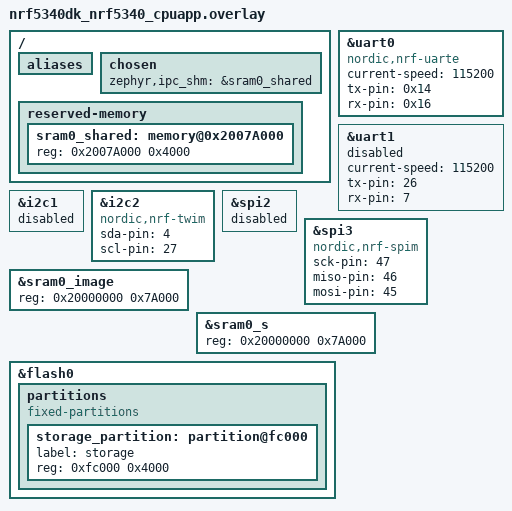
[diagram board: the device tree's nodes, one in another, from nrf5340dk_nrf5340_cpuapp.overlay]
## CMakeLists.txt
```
# SPDX-License-Identifier: Apache-2.0

cmake_minimum_required(VERSION 3.13.1)

find_package(Zephyr REQUIRED HINTS $ENV{ZEPHYR_BASE})
project(comprensive_example)

# NORDIC SDK APP START

target_sources(app PRIVATE src/main.c)

target_sources_ifdef(CONFIG_EXAMPLE_IIC app
                     PRIVATE src/iic_thread.c)
					 
target_sources_ifdef(CONFIG_EXAMPLE_SPIM app
                     PRIVATE src/spi_thread.c)
					 
target_sources_ifdef(CONFIG_EXAMPLE_HS_UART app
                     PRIVATE src/uart_thread.c)
					 
target_sources_ifdef(CONFIG_EXAMPLE_ADC app
                     PRIVATE src/adc_thread.c)
					 
target_sources_ifdef(CONFIG_RPC_REMOTE_API app
                     PRIVATE src/rpc_app_api_general.c src/rpc_app_api.c src/rpc_thread.c)
				 

target_sources_ifdef(CONFIG_RPC_SMP_BT app
                     PRIVATE src/rpc_app_smp_bt.c)		

target_sources_ifdef(CONFIG_EXAMPLE_FLASH app
                     PRIVATE src/flash_thread.c)

target_sources_ifdef(CONFIG_EXAMPLE_RAW_NRFX app
                      PRIVATE src/raw_nrfx_driver_thread.c)


zephyr_library_include_directories(.)

# NORDIC SDK APP END
```

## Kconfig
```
#
# Copyright (c) 2018 Nordic Semiconductor ASA
#
# SPDX-License-Identifier: LicenseRef-BSD-5-Clause-Nordic
#

source "Kconfig.zephyr"
menu "nRF53 BLE custom"

config BLE_NETWORK_CORE
	bool "Both BLE host and controller run on network core"
	help
	  Enable the whole BLE stack running on network core

config EXAMPLE_IIC
	bool "load IIC example or not"
	help
		if yes, load IIC example
		
config EXAMPLE_SPIM
	bool "load SPI master example or not"
	help
		if yes, load SPI master example		
		
config EXAMPLE_EXT_INT
	bool "load external IO interrupt example or not"
	help
		if yes, load external IO interrupt example

config EXAMPLE_ADC
	bool "load ADC example or not"
	help
		if yes, load ADC example		

config EXAMPLE_HS_UART
	bool "load high speed UART example or not"
	help
		if yes, load high speed UART example	  

config EXAMPLE_FLASH
	bool "load Flash access usage example"
	default n
	help
		if yes, load Flash access usage example

config EXAMPLE_RAW_NRFX
	bool "load raw nrfx driver(spim3 & rtc) usage example"
	default n
	help
		if yes, load raw spim3 & rtc API usage example	

config RPC_REMOTE_API
	bool "app core and net core communicate by remote API. that is, app core can call net core API, and net core can also call app core API"
	help
	  enable the RPC api mode
	  
config RPC_SMP_BT
	bool "(test purpose) load DFU example over BLE SMP"
	help
		if yes, load DFU example over BLE SMP		

config NCS_OLD
	bool "use NCS v1.5.1 or earlier API"
	help
		use NCS v1.5.1 or earlier API
		
module = NRF53_EXAMPLES_CONFIG
module-str = nrf53 specific examples configurations
source "${ZEPHYR_BASE}/subsys/logging/Kconfig.template.log_config"

endmenu
```

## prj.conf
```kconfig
CONFIG_NFCT_PINS_AS_GPIOS=y

## thread monitor ##
CONFIG_THREAD_ANALYZER=y
CONFIG_THREAD_NAME=y

## logging configurations ##
CONFIG_ASSERT=y
CONFIG_ASSERT_LEVEL=2

CONFIG_LOG=y
CONFIG_LOG_DEFAULT_LEVEL=3
CONFIG_LOG_BACKEND_UART=y
CONFIG_LOG_BACKEND_RTT=n
CONFIG_LOG_BACKEND_RTT_MODE_DROP=y
CONFIG_LOG_MODE_OVERFLOW=y
CONFIG_LOG_PRINTK=y
CONFIG_LOG_PRINTK_MAX_STRING_LENGTH=256
CONFIG_LOG_BUFFER_SIZE=4096
CONFIG_LOG_BACKEND_RTT_MESSAGE_SIZE=256
CONFIG_LOG_STRDUP_BUF_COUNT=64
CONFIG_LOG_STRDUP_MAX_STRING=64
CONFIG_LOG_BACKEND_SHOW_COLOR=n
CONFIG_LOG_BACKEND_FORMAT_TIMESTAMP=y
## CONFIG_LOG_IMMEDIATE=y

CONFIG_CONSOLE=y
CONFIG_USE_SEGGER_RTT=n
CONFIG_SEGGER_RTT_BUFFER_SIZE_UP=4096
CONFIG_RTT_CONSOLE=n
CONFIG_UART_CONSOLE=y

#change logging backend to RTT
# CONFIG_LOG_BACKEND_UART=n
# CONFIG_LOG_BACKEND_RTT=y
# CONFIG_USE_SEGGER_RTT=y
# CONFIG_RTT_CONSOLE=y
# CONFIG_UART_CONSOLE=n

## peripherals ##
CONFIG_GPIO=y
CONFIG_DK_LIBRARY=y

## stack size configurations ##
CONFIG_SYSTEM_WORKQUEUE_STACK_SIZE=2400
# CONFIG_ISR_STACK_SIZE=2048
CONFIG_HEAP_MEM_POOL_SIZE=12288
CONFIG_LOG_PROCESS_THREAD_STACK_SIZE=1024
CONFIG_MAIN_STACK_SIZE=2048

# enable network core
CONFIG_BOARD_ENABLE_CPUNET=y


## RPC example configurations ##
CONFIG_RPC_REMOTE_API=y

CONFIG_IPM=y
CONFIG_IPM_NRFX=y
CONFIG_IPM_MSG_CH_1_ENABLE=y
CONFIG_IPM_MSG_CH_1_TX=y
CONFIG_IPM_MSG_CH_0_ENABLE=y
CONFIG_IPM_MSG_CH_0_RX=y
CONFIG_OPENAMP=y
CONFIG_NRF_RPC=y

CONFIG_TINYCBOR=y
CONFIG_RPMSG_MASTER=y
CONFIG_THREAD_CUSTOM_DATA=y
CONFIG_NRF_RPC_CBOR=y
CONFIG_NRF_RPC_THREAD_STACK_SIZE=2048
CONFIG_NRF_RPC_LOG_LEVEL_INF=y
CONFIG_NRF_RPC_TR_LOG_LEVEL_INF=y
CONFIG_NRF_RPC_OS_LOG_LEVEL_INF=y


## I2C master example ##
CONFIG_EXAMPLE_IIC=y
CONFIG_I2C=y
CONFIG_NRFX_TWIM=y
CONFIG_NRFX_TWIM2=y

## external interrupt example (in IIC thread) ##
CONFIG_EXAMPLE_EXT_INT=y

## high speed uart example ##
CONFIG_EXAMPLE_HS_UART=y
CONFIG_SERIAL=y
CONFIG_UART_ASYNC_API=y
CONFIG_NRFX_UARTE1=y
CONFIG_UART_1_NRF_HW_ASYNC=y
CONFIG_UART_1_NRF_HW_ASYNC_TIMER=2
CONFIG_NRFX_UARTE0=y
CONFIG_UART_0_NRF_HW_ASYNC=y
CONFIG_UART_0_NRF_HW_ASYNC_TIMER=1

## SPI master example ##
CONFIG_EXAMPLE_SPIM=y
CONFIG_SPI=y
CONFIG_NRFX_SPIM3=y

## raw nrfx(spim3 & rtc0) driver API usage example ##
# CONFIG_EXAMPLE_RAW_NRFX=y
# CONFIG_NRFX_SPIM3=y
# CONFIG_NRFX_RTC0=y

## Load ADC example ##
CONFIG_EXAMPLE_ADC=y
CONFIG_ADC=y
CONFIG_ADC_ASYNC=y
CONFIG_ADC_NRFX_SAADC=y

## Flash access usage example ##
CONFIG_EXAMPLE_FLASH=y
CONFIG_FLASH=y
CONFIG_FLASH_PAGE_LAYOUT=y
CONFIG_FLASH_MAP=y
CONFIG_NVS=y
CONFIG_MPU_ALLOW_FLASH_WRITE=y
CONFIG_SETTINGS=y

## Device power management example ##
## CONFIG_DEVICE_POWER_MANAGEMENT is deprecated from NCSv1.5.0. Use CONFIG_PM_DEVICE instead
CONFIG_PM_DEVICE=y

## common DFU setting ##
CONFIG_BLE_NETWORK_CORE=y
CONFIG_NRF53_UPGRADE_NETWORK_CORE=y
CONFIG_BOOTLOADER_MCUBOOT=y

## Open the following config to run SMP DFU ##
# CONFIG_MCUMGR=y
# CONFIG_MCUMGR_CMD_IMG_MGMT=y
# CONFIG_MCUMGR_CMD_OS_MGMT=y
# CONFIG_OS_MGMT_TASKSTAT=n
# CONFIG_OS_MGMT_ECHO=y
# CONFIG_IMG_BLOCK_BUF_SIZE=2048
# CONFIG_MCUMGR_BUF_SIZE=256
# CONFIG_MCUMGR_BUF_COUNT=4
# CONFIG_MGMT_CBORATTR_MAX_SIZE=512
# ## CONFIG_IMG_ERASE_PROGRESSIVELY=y

# ## SMP BLE DFU via RPC config ##
# CONFIG_RPC_SMP_BT=y

## SMP UART DFU config ##
# CONFIG_MCUMGR_SMP_UART=y
# CONFIG_UART_MCUMGR_RX_BUF_SIZE=256
# CONFIG_UART_MCUMGR_RX_BUF_COUNT=2
# CONFIG_UART_0_INTERRUPT_DRIVEN=y

## Open the following config to run nrf_dfu OTA ##
CONFIG_NRF_DFU=y
CONFIG_NRF_DFU_RPC_APP=y
# CONFIG_NRF_DFU_LOG_LEVEL=3
CONFIG_IMG_MANAGER=y
CONFIG_MCUBOOT_IMG_MANAGER=y
CONFIG_IMG_BLOCK_BUF_SIZE=4096

## Open the following kconfig to put secondary slot on external Flash ##
## mcuboot.conf should do the correspondent changes too ##
CONFIG_PM_EXTERNAL_FLASH=y
CONFIG_PM_EXTERNAL_FLASH_DEV_NAME="MX25R64"
CONFIG_PM_EXTERNAL_FLASH_BASE=0x0
CONFIG_PM_EXTERNAL_FLASH_SIZE=0x800000
CONFIG_NORDIC_QSPI_NOR=y
CONFIG_NORDIC_QSPI_NOR_FLASH_LAYOUT_PAGE_SIZE=4096
CONFIG_NORDIC_QSPI_NOR_STACK_WRITE_BUFFER_SIZE=16
# Set the settings storage size
CONFIG_PM_PARTITION_SIZE_SETTINGS_STORAGE=0x4000

## To run the example in NCS v1.5.1 or earlier, open the following configurations
# CONFIG_NCS_V1_5_1=y
```

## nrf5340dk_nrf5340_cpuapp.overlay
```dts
/* overlay file for app core */

&uart0 {
	compatible = "nordic,nrf-uarte";
	status = "okay";
	current-speed = < 115200 >;	
	tx-pin = < 0x14 >;
	rx-pin = < 0x16 >;
	/* delete rts-pin&cts-pin to release the related 2 pins for other uses */
	/delete-property/ rts-pin;
	/delete-property/ cts-pin;
};

&uart1 {
	status = "disabled";
	current-speed = < 115200 >;
	tx-pin = < 26 >;
	rx-pin = < 7 >;
};

&i2c1 {
	status = "disabled";
};

&i2c2 {
	status = "okay";
	compatible = "nordic,nrf-twim";
	sda-pin = <4>;
	scl-pin = <27>;
};

&spi2 {
	status = "disabled";
};

&spi3 {
	status = "okay"; 
	compatible = "nordic,nrf-spim";
	sck-pin = < 47 >;
	miso-pin = < 46 >;
	mosi-pin = < 45 >;
};

/* delete button4 to initialize the related pin for network core use */
/ {
 aliases {  
  /delete-property/ sw3;
 };
};

/delete-node/ &button3;

/* adjust the RAM size of application image */
&sram0_image{
	reg = < 0x20000000 0x7A000 >;
};

&sram0_s{
	reg = < 0x20000000 0x7A000 >;
};

/delete-node/ &sram0_shared;

/ {
	chosen {
		/* shared memory reserved for the inter-processor communication */
		zephyr,ipc_shm = &sram0_shared;
	};

	reserved-memory {
		#address-cells = <1>;
		#size-cells = <1>;
		ranges;	
		sram0_shared: memory@0x2007A000 {
			/* SRAM allocated to shared memory */
			reg = <0x2007A000 0x4000>;
		};
	};
};

/delete-node/ &storage_partition;
&flash0{
		partitions {
			compatible = "fixed-partitions";
			#address-cells = < 0x1 >;
			#size-cells = < 0x1 >;

			storage_partition: partition@fc000 {
				label = "storage";
				reg = < 0xfc000 0x4000 >;
			};
		};
};
```

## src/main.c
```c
/*
 * Copyright (c) 2020 Nordic Semiconductor ASA
 *
 * SPDX-License-Identifier: LicenseRef-BSD-5-Clause-Nordic
 */

#include <zephyr.h>
#include <device.h>
#include <devicetree.h>
#include <drivers/gpio.h>
#include <stdio.h>
#include <dk_buttons_and_leds.h>
#include <nrf.h>
#include <nrfx.h>
#include <drivers/uart.h>
#ifdef CONFIG_MCUMGR_CMD_IMG_MGMT
#include "img_mgmt/img_mgmt.h"
#endif
#ifdef CONFIG_MCUMGR_CMD_OS_MGMT
#include "os_mgmt/os_mgmt.h"
#endif
#ifdef CONFIG_RPC_SMP_BT
#include "rpc_app_smp_bt.h"
#include <img_mgmt/img_mgmt_impl.h>
#endif
#ifdef CONFIG_NRF_DFU
#include "nrf_dfu_settings.h"
#include "nrf_dfu.h"
#include "power/reboot.h"
#include "nrf_dfu.h"
#include "nrf_dfu_validation.h"
#endif
#include <logging/log.h>
#include <logging/log_ctrl.h>
#define LOG_MODULE_NAME main
LOG_MODULE_REGISTER(LOG_MODULE_NAME);

#define ERASE_DELAY_AFTER_BOOT 30   //unit: s
#ifndef CONFIG_NCS_V1_5_1
static struct k_work_delayable blinky_work;
#else
static struct k_delayed_work blinky_work;
#endif

K_SEM_DEFINE(sem_rpc_tx, 0, 1);
K_SEM_DEFINE(sem_spi_txrx, 0, 1);
K_SEM_DEFINE(sem_raw_nrfx_txrx, 0, 1);
/* Stack definition for application workqueue */
K_THREAD_STACK_DEFINE(application_stack_area,
		      1024);
static struct k_work_q application_work_q;

/* The devicetree node identifier for the "led0" alias. */
#define LED0_NODE DT_ALIAS(led0)

#if DT_NODE_HAS_STATUS(LED0_NODE, okay)
#define LED0	DT_GPIO_LABEL(LED0_NODE, gpios)
#define LED0_PIN	DT_GPIO_PIN(LED0_NODE, gpios)
#define LED0_FLAGS	DT_GPIO_FLAGS(LED0_NODE, gpios)
#else
/* A build error here means your board isn't set up to blink an LED. */
#error "Unsupported board: led0 devicetree alias is not defined"
#define LED0	""
#define PIN	0
#define FLAGS	0
#endif

#ifdef CONFIG_PM_DEVICE

const struct device *devUart0;
const struct device *devUart1;

static void get_device_handle(void)
{
	devUart0 = device_get_binding("UART_0");
    devUart1 = device_get_binding("UART_1");
}
#ifdef CONFIG_NCS_V1_5_1
void set_device_pm_state(void)
{
	int err;
	uint32_t pm_state;

	device_get_power_state(devUart1, &pm_state);
	if (pm_state == DEVICE_PM_SUSPEND_STATE)
	{
		LOG_INF("UART1 is in suspend state. We activate it");
		err = device_set_power_state(devUart1,
						DEVICE_PM_ACTIVE_STATE,
						NULL, NULL);
		if (err) {
			LOG_ERR("UART1 enable failed");			
		}
		else
		{
			LOG_INF("## UART1 is actvie now ##");
		}		
	}
	else if (pm_state == DEVICE_PM_ACTIVE_STATE)
	{
		LOG_INF("UART1 is in active state. We suspend it");
		err = device_set_power_state(devUart1,
						DEVICE_PM_SUSPEND_STATE,
						NULL, NULL);
		if (err) {
			LOG_ERR("UART1 disable failed");
		}
		else
		{
			LOG_INF("## UART1 is suspended now ##");
		}		
	}



	device_get_power_state(devUart0, &pm_state);
	if (pm_state == DEVICE_PM_SUSPEND_STATE)
	{
		LOG_INF("UART0 is in suspend state. We activate it");
		err = device_set_power_state(devUart0,
						DEVICE_PM_ACTIVE_STATE,
						NULL, NULL);
		if (err) {
			LOG_ERR("UART0 enable failed");			
		}
		else
		{
			LOG_INF("## UART0 is active now ##");
		}		
	}
	else if (pm_state == DEVICE_PM_ACTIVE_STATE)
	{
		LOG_INF("UART0 is in active state. We suspend it");
		//print out all the pending logging messages
		while(log_process(false));
		err = device_set_power_state(devUart0,
						DEVICE_PM_SUSPEND_STATE,
						NULL, NULL);
		if (err) {
			LOG_ERR("UART0 disable failed");
		}
		else
		{
			LOG_INF("## UART0 is suspended now ##");
		}		
	}

}
#else
void set_device_pm_state(void)
{
	int err;
	uint32_t pm_state;

	if (devUart1)
	{
		pm_device_state_get(devUart1, &pm_state);
		if (pm_state == PM_DEVICE_STATE_SUSPEND)
		{
			LOG_INF("UART1 is in suspend state. We activate it");
			err = pm_device_state_set(devUart1,
							PM_DEVICE_STATE_ACTIVE,
							NULL, NULL);
			if (err) {
				LOG_ERR("UART1 enable failed");			
			}
			else
			{
				LOG_INF("## UART1 is active now ##");
			}		
		}
		else if (pm_state == PM_DEVICE_STATE_ACTIVE)
		{
			LOG_INF("UART1 is in active state. We suspend it");

#if CONFIG_UART_ASYNC_API && CONFIG_UART_1_NRF_HW_ASYNC
		((const struct uart_driver_api *)devUart1->api)->rx_disable(devUart1);
#endif			
			err = pm_device_state_set(devUart1,
							PM_DEVICE_STATE_SUSPEND,
							NULL, NULL);
			if (err) {
				LOG_ERR("UART1 disable failed");
			}
			else
			{
				LOG_INF("## UART1 is suspended now ##");
			}		
		}
	}

	pm_device_state_get(devUart0, &pm_state);
	if (pm_state == PM_DEVICE_STATE_SUSPEND)
	{
		LOG_INF("UART0 is in suspend state. We activate it");
		err = pm_device_state_set(devUart0,
						PM_DEVICE_STATE_ACTIVE,
						NULL, NULL);
		if (err) {
			LOG_ERR("UART0 enable failed");			
		}
		else
		{
			LOG_INF("## UART0 is active now ##");
		}		
	}
	else if (pm_state == PM_DEVICE_STATE_ACTIVE)
	{
		LOG_INF("UART0 is in active state. We suspend it");
		//print out all the pending logging messages
		while(log_process(false));

#if CONFIG_UART_ASYNC_API && CONFIG_UART_0_NRF_HW_ASYNC
		((const struct uart_driver_api *)devUart0->api)->rx_disable(devUart0);
#endif
		err = pm_device_state_set(devUart0,
						PM_DEVICE_STATE_SUSPEND,
						NULL, NULL);
		if (err) {
			LOG_ERR("UART0 disable failed");
		}
		else
		{
			LOG_INF("## UART0 is suspended now ##");
		}		
	}

}
#endif //CONFIG_NCS_V1_5_1

#endif //CONFIG_PM_DEVICE

void button_changed(uint32_t button_state, uint32_t has_changed)
{
	uint32_t buttons = button_state & has_changed;
	
	if (buttons & DK_BTN1_MSK) {
		LOG_INF("button1 isr");
		k_sem_give(&sem_rpc_tx);		
	}

	if (buttons & DK_BTN2_MSK) {
		LOG_INF("button2 isr");
		k_sem_give(&sem_spi_txrx);
		k_sem_give(&sem_raw_nrfx_txrx);		
	}

	if (buttons & DK_BTN3_MSK) {
		LOG_INF("button3 isr");
#ifdef CONFIG_PM_DEVICE		
		set_device_pm_state();
#endif		
	}			
}

const struct device *ledDev;
bool led_is_on = true;

static void blinky_work_fn(struct k_work *work)
{
    //printk("blinky fn in system workqueue\n");
	gpio_pin_set(ledDev, LED0_PIN, (int)led_is_on);
	led_is_on = !led_is_on;

#ifndef CONFIG_NCS_V1_5_1
	k_work_reschedule_for_queue(&application_work_q, &blinky_work,
					   	K_SECONDS(2));
#else
    //k_delayed_work_submit(&blinky_work, K_SECONDS(2));
	k_delayed_work_submit_to_queue(&application_work_q, &blinky_work,
				       K_SECONDS(2));
#endif

}

static void assign_io_to_netcore(void)
{
	NRF_P0_S->PIN_CNF[9] = (GPIO_PIN_CNF_MCUSEL_NetworkMCU <<
					GPIO_PIN_CNF_MCUSEL_Pos);
}

// #ifdef CONFIG_NCS_V1_5_1
// static struct k_delayed_work erase_slot_work;
// #else
// static struct k_work_delayable erase_slot_work;
// #endif //CONFIG_NCS_V1_5_1
// static void erase_work_fn(struct k_work *work)
// {   	
//    	img_mgmt_impl_erase_slot();
// 	LOG_WRN("Time is out and erase the secondary slot to speed up DFU");
// }

#ifdef CONFIG_NRF_DFU
/**@brief Function for handling DFU events.
 */
static void dfu_observer(nrf_dfu_evt_type_t evt_type)
{
    switch (evt_type)
    {
        case NRF_DFU_EVT_DFU_STARTED:
        case NRF_DFU_EVT_OBJECT_RECEIVED:

            break;
        case NRF_DFU_EVT_DFU_COMPLETED:
        case NRF_DFU_EVT_DFU_ABORTED:
			LOG_INF("resetting...");
			while(log_process(false));
            sys_reboot(SYS_REBOOT_WARM);
            break;
        case NRF_DFU_EVT_TRANSPORT_DEACTIVATED:
            // Reset the internal state of the DFU settings to the last stored state.
			LOG_INF("NRF_DFU_EVT_TRANSPORT_DEACTIVATED");
            nrf_dfu_settings_reinit();
            break;
        default:
            break;
    }

}

int dfu_init(void)
{
    int ret_val;

    ret_val = nrf_dfu_settings_init(true);
    if (ret_val != NRF_SUCCESS)
	{
		LOG_WRN("dfu settings init err %d", ret_val);
	}

    ret_val = nrf_dfu_init(dfu_observer);
    if (ret_val != NRF_SUCCESS)
	{
		LOG_WRN("dfu init err %d", ret_val);
	}

    return ret_val;
}
#endif //CONFIG_NRF_DFU

void main(void)
{
	int err;	

	LOG_INF("### comprensive examples @ appcore version v0.1 compiled at %s %s\n", __TIME__, __DATE__);
	assign_io_to_netcore();

	ledDev = device_get_binding(LED0);
	if (ledDev == NULL) {
		return;
	}

#ifdef CONFIG_PM_DEVICE
	get_device_handle();
#endif

	err = gpio_pin_configure(ledDev, LED0_PIN, GPIO_OUTPUT_ACTIVE | LED0_FLAGS);
	if (err < 0) {
		printk("gpio configure error %d \n", err);
		return;
	}

	err = dk_buttons_init(button_changed);
	if (err) {
		printk("Cannot init buttons (err: %d)", err);
	}

#ifndef CONFIG_NCS_V1_5_1
	k_work_queue_start(&application_work_q, application_stack_area,
			   K_THREAD_STACK_SIZEOF(application_stack_area), 10,
			   NULL);
	k_work_init_delayable(&blinky_work, blinky_work_fn);
	k_work_reschedule_for_queue(&application_work_q, &blinky_work,
					   	K_MSEC(20));	
#else
	k_work_q_start(&application_work_q, application_stack_area,
		       K_THREAD_STACK_SIZEOF(application_stack_area),
		       10);
	k_delayed_work_init(&blinky_work, blinky_work_fn);
	// k_delayed_work_submit(&blinky_work, K_MSEC(20));
	k_delayed_work_submit_to_queue(&application_work_q, &blinky_work,
				       K_MSEC(20));				   	
#endif

#ifdef CONFIG_RPC_SMP_BT
	LOG_INF("## OTA/Serial DFU example ##");	
#ifdef CONFIG_MCUMGR_CMD_OS_MGMT
	os_mgmt_register_group();
#endif	
#ifdef CONFIG_MCUMGR_CMD_IMG_MGMT
	img_mgmt_register_group();
#endif //CONFIG_MCUMGR_CMD_IMG_MGMT
// #ifdef CONFIG_NCS_V1_5_1
// 	k_delayed_work_init(&erase_slot_work, erase_work_fn);
// 	k_delayed_work_submit(&erase_slot_work, K_SECONDS(ERASE_DELAY_AFTER_BOOT));
// #else
// 	k_work_init_delayable(&erase_slot_work, erase_work_fn);
// 	k_work_reschedule(&erase_slot_work, K_SECONDS(ERASE_DELAY_AFTER_BOOT));
// #endif
#endif  //CONFIG_RPC_SMP_BT

#ifdef CONFIG_NRF_DFU
	err = dfu_init();
	if (err) {
		LOG_ERR("dfu service init err %d", err);		
	}
#endif //CONFIG_NRF_DFU
	//main thread 
	// while(1)
	// {
	// 	//add your code here
	// 	k_sleep(K_SECONDS(2));
	// 	printk("main thread");
	// }
	//since we don't put any work in main thread, exit directly
	LOG_WRN("exit main thread\n");
}
```

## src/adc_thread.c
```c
/*
 * Copyright (c) 2020 Nordic Semiconductor ASA
 *
 * SPDX-License-Identifier: LicenseRef-BSD-5-Clause-Nordic
 */

#include <zephyr.h>
#include <device.h>
#include <devicetree.h>
#include <drivers/gpio.h>
#include <logging/log.h>
#include <drivers/adc.h>
#include <hal/nrf_saadc.h>

LOG_MODULE_REGISTER(adc_thread, 3);

#define NUM_OF_CH 2
#define ADC_DEVICE_NAME		DT_LABEL(DT_NODELABEL(adc))
#define ADC_RESOLUTION		12
#define ADC_OVERSAMPLING	4 /* 2^ADC_OVERSAMPLING samples are averaged */
#define ADC_MAX 		4096
#define BATTERY_MEAS_VOLTAGE_GAIN	6
#define ADC_GAIN		ADC_GAIN_1_6
#define ADC_REFERENCE		ADC_REF_INTERNAL
#define ADC_REF_INTERNAL_MV	600UL
#define ADC_ACQUISITION_TIME	ADC_ACQ_TIME(ADC_ACQ_TIME_MICROSECONDS, 10)
#define ADC_CHANNEL_ID		0
#define ADC_CHANNEL_INPUT	NRF_SAADC_INPUT_VDD
#define ADC_CHANNEL_ID2		1
#define ADC_CHANNEL_INPUT2	NRF_SAADC_INPUT_AIN1   //P0.05
/* ADC asynchronous read is scheduled on odd works. Value read happens during
 * even works. This is done to avoid creating a thread for battery monitor.
 */
#define ADC_SAMPLE_INTERVAL	20  //unit:s

#define BATTERY_VOLTAGE(sample) (sample * BATTERY_MEAS_VOLTAGE_GAIN	\
				 * ADC_REF_INTERNAL_MV / ADC_MAX)


static const struct device *adc_dev;
static int16_t adc_buffer[NUM_OF_CH];
static bool adc_async_read_pending;

#ifndef CONFIG_NCS_V1_5_1
static struct k_work_delayable adc_work;
#else
static struct k_delayed_work adc_work;
#endif

static struct k_poll_signal async_sig = K_POLL_SIGNAL_INITIALIZER(async_sig);
static struct k_poll_event  async_evt =
	K_POLL_EVENT_INITIALIZER(K_POLL_TYPE_SIGNAL,
				 K_POLL_MODE_NOTIFY_ONLY,
				 &async_sig);

static struct adc_sequence sequence = {
	.options	= NULL,
	.channels	= BIT(ADC_CHANNEL_ID),
	.buffer		= adc_buffer,
	.buffer_size	= sizeof(adc_buffer),
	.resolution	= ADC_RESOLUTION,
	.oversampling	= ADC_OVERSAMPLING,
	.calibrate	= false,
};
static struct adc_sequence sequence_calibrate = {
	.options	= NULL,
	.channels	= BIT(ADC_CHANNEL_ID),
	.buffer		= adc_buffer,
	.buffer_size	= sizeof(adc_buffer),
	.resolution	= ADC_RESOLUTION,
	.oversampling	= ADC_OVERSAMPLING,
	.calibrate	= true,
};

static bool calibrated;

void adc_sample_sync(void)
{
	int err;

	if (NUM_OF_CH == 2)
	{
		sequence.channels = BIT(ADC_CHANNEL_ID) | BIT(ADC_CHANNEL_ID2);
		sequence_calibrate.channels = BIT(ADC_CHANNEL_ID) | BIT(ADC_CHANNEL_ID2);
		sequence.oversampling  = NRF_SAADC_OVERSAMPLE_DISABLED;
		sequence_calibrate.oversampling  = NRF_SAADC_OVERSAMPLE_DISABLED;
	}
	if (likely(calibrated)) {		
		err = adc_read(adc_dev, &sequence);
	} else {
		err = adc_read(adc_dev, &sequence_calibrate);
		calibrated = true;
	}
	if (err) {
		LOG_WRN("ADC read err %d", err);
	} else {
		for (int i = 0; i < NUM_OF_CH; i++)
		{
			uint32_t voltage = BATTERY_VOLTAGE(adc_buffer[i]);
			LOG_INF("Voltage%d: %u mV / %d", i, voltage, adc_buffer[i]);
		}
	}			
}
#ifdef CONFIG_ADC_ASYNC
static void adc_sample_async(struct k_work *work)
{
	int err;

	if (NUM_OF_CH == 2)
	{
		sequence.channels = BIT(ADC_CHANNEL_ID) | BIT(ADC_CHANNEL_ID2);
		sequence_calibrate.channels = BIT(ADC_CHANNEL_ID) | BIT(ADC_CHANNEL_ID2);
		sequence.oversampling  = NRF_SAADC_OVERSAMPLE_DISABLED;
		sequence_calibrate.oversampling  = NRF_SAADC_OVERSAMPLE_DISABLED;		
	}
	if (!adc_async_read_pending) {
		if (likely(calibrated)) {
			err = adc_read_async(adc_dev, &sequence, &async_sig);
		} else {
			err = adc_read_async(adc_dev, &sequence_calibrate,
					     &async_sig);
			calibrated = true;
		}

		if (err) {
			LOG_WRN("adc_read_async err %d", err);
		} else {
			adc_async_read_pending = true;
		}
	} else {
		err = k_poll(&async_evt, 1, K_NO_WAIT);
		if (err) {
			LOG_WRN("ADC sampling timeout");
		} else {
			adc_async_read_pending = false;			
			for (int i = 0; i < NUM_OF_CH; i++)
			{
				uint32_t voltage = BATTERY_VOLTAGE(adc_buffer[i]);
				LOG_INF("Voltage%d: %u mV / %d async", i, voltage, adc_buffer[i]);
			}			
		}
	}
#ifndef CONFIG_NCS_V1_5_1
	k_work_reschedule(&adc_work, K_SECONDS(ADC_SAMPLE_INTERVAL));
#else
	k_delayed_work_submit(&adc_work, K_SECONDS(ADC_SAMPLE_INTERVAL));
#endif	

}
#endif

static int init_adc(void)
{
	int err;

	adc_dev = device_get_binding(ADC_DEVICE_NAME);
	if (!adc_dev) {
		LOG_ERR("Cannot get ADC device");
		return -ENXIO;
	}

	struct adc_channel_cfg channel_cfg = {
		.gain             = ADC_GAIN,
		.reference        = ADC_REFERENCE,
		.acquisition_time = ADC_ACQUISITION_TIME,
		.channel_id       = ADC_CHANNEL_ID,
		.differential	  = 0,
#if defined(CONFIG_ADC_CONFIGURABLE_INPUTS)
		.input_positive   = ADC_CHANNEL_INPUT,
#endif
	};
	err = adc_channel_setup(adc_dev, &channel_cfg);
	if (err) {
		LOG_ERR("Setting up the ADC channel%d failed", ADC_CHANNEL_ID);
		return err;
	}

	if (NUM_OF_CH == 2)
	{
		channel_cfg.channel_id = ADC_CHANNEL_ID2;
		channel_cfg.input_positive = ADC_CHANNEL_INPUT2;
		err = adc_channel_setup(adc_dev, &channel_cfg);
		if (err) {
			LOG_ERR("Setting up the ADC channel%d failed", ADC_CHANNEL_ID2);
			return err;
		}		
	}


#ifdef CONFIG_ADC_ASYNC
#ifndef CONFIG_NCS_V1_5_1
	k_work_init_delayable(&adc_work, adc_sample_async);
	k_work_reschedule(&adc_work, K_MSEC(10));
#else
	k_delayed_work_init(&adc_work, adc_sample_async);
	k_delayed_work_submit(&adc_work, K_MSEC(10));
#endif //CONFIG_NCS_V1_5_1	
#endif //CONFIG_ADC_ASYNC

	return 0;
}


void adc_thread(void)
{	
	
	LOG_INF("**ADC sampling example");
	init_adc();

	while (1) {                
        LOG_INF("ADC thread");
        adc_sample_sync();
        k_sleep(K_SECONDS(ADC_SAMPLE_INTERVAL)); 
	}
}

K_THREAD_DEFINE(adc_thread_id, 1024, adc_thread, NULL, NULL,
		NULL, 8, 0, 0);
```

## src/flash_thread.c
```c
/*
 * Copyright (c) 2020 Nordic Semiconductor ASA
 *
 * SPDX-License-Identifier: LicenseRef-BSD-5-Clause-Nordic
 */

#include <zephyr.h>
#include <power/reboot.h>
#include <device.h>
#include <string.h>
#include <drivers/flash.h>
#include <storage/flash_map.h>
#include <fs/nvs.h>
#include "settings/settings.h"
#include <logging/log.h>

#define LOG_MODULE_NAME flash_thread
LOG_MODULE_REGISTER(LOG_MODULE_NAME);

static struct nvs_fs fs;

#define KEY_ID 1
#define RBT_CNT_ID 2

int nvs_usage_init(void)
{
	int rc;
	
	uint8_t key[8];
	uint32_t reboot_counter = 0U;

	const struct flash_area *fa;
	struct flash_sector hw_flash_sector;
	uint32_t sector_cnt = 1;

	rc = flash_area_open(FLASH_AREA_ID(storage), &fa);
	if (rc) {
		printk("storage area open failed %d", rc);
		return rc;
	}
	
	rc = flash_area_get_sectors(FLASH_AREA_ID(storage), &sector_cnt,
				    &hw_flash_sector);
	if (rc) {
		printk("sector info retrive err %d", rc);
		return rc;
	} 

	fs.sector_size = hw_flash_sector.fs_size;
	fs.sector_count = sector_cnt;

	printk("NVS sector size=%d sector count=%d\n", fs.sector_size, fs.sector_count);

	// struct flash_pages_info info;

	// /* define the nvs file system by settings with:
	//  *	sector_size equal to the pagesize,
	//  *	3 sectors
	//  *	starting at FLASH_AREA_OFFSET(storage)
	//  */
	// fs.offset = FLASH_AREA_OFFSET(storage);
	// LOG_INF("NVS flash offset %x ", fs.offset);
	// rc = flash_get_page_info_by_offs(
	// 	device_get_binding(DT_CHOSEN_ZEPHYR_FLASH_CONTROLLER_LABEL),
	// 	fs.offset, &info);
	// if (rc) {
	// 	printk("Unable to get page info");
	// }
	// fs.sector_size = info.size;
	// fs.sector_count = 3U;

	rc = nvs_init(&fs, DT_CHOSEN_ZEPHYR_FLASH_CONTROLLER_LABEL);
	if (rc) {
		printk("Flash Init failed\n");
	}


	/* KEY_ID is used to store a key, lets see if we can read it from flash
	 */
	rc = nvs_read(&fs, KEY_ID, &key, sizeof(key));
	if (rc > 0) { /* item was found, show it */
		LOG_HEXDUMP_INF(key, sizeof(key), "Key value in NVS:");
	} else   {/* item was not found, add it */
		LOG_INF("No key found, adding it at id %d by NVS API", KEY_ID);
		key[0] = 0xFF;
		key[1] = 0xFE;
		key[2] = 0xFD;
		key[3] = 0xFC;
		key[4] = 0xFB;
		key[5] = 0xFA;
		key[6] = 0xF9;
		key[7] = 0xF8;
		(void)nvs_write(&fs, KEY_ID, &key, sizeof(key));
	}
	/* RBT_CNT_ID is used to store the reboot counter, lets see
	 * if we can read it from flash
	 */
	reboot_counter = 0;
	rc = nvs_read(&fs, RBT_CNT_ID, &reboot_counter, sizeof(reboot_counter));
	if (rc > 0) { /* item was found, show it */
		LOG_INF("*** Reboot counter in NVS: %d ***",
			reboot_counter);
	}
	LOG_INF("save new reboot counter by NVS API"); 
	reboot_counter++;
	(void)nvs_write(&fs, RBT_CNT_ID, &reboot_counter,
			  sizeof(reboot_counter));

	return 0;	
}


static uint32_t reboot_cnt;
static uint8_t key_s[8];

int alpha_handle_set(const char *name, size_t len, settings_read_cb read_cb,
		  void *cb_arg)
{
	const char *next;
	int rc;

	LOG_INF("set handler name=%s, len=%d ", log_strdup(name), len);
	if (settings_name_steq(name, "boot_cnt", &next) && !next) {
		if (len != sizeof(reboot_cnt)) {
			return -EINVAL;
		}
		rc = read_cb(cb_arg, &reboot_cnt, sizeof(reboot_cnt));
		LOG_INF("*** Reboot counter in Settings: %d ****", reboot_cnt);
		return 0;
	}

	if (settings_name_steq(name, "key", &next) && !next) {
		if (len != sizeof(key_s)) {
			return -EINVAL;
		}
		rc = read_cb(cb_arg, key_s, sizeof(key_s));
		LOG_HEXDUMP_INF(key_s, sizeof(key_s), "Key value in Settings:");
		return 0;
	}

	return -ENOENT;
}


/* dynamic main tree handler */
struct settings_handler alph_handler = {
		.name = "alpha",
		.h_get = NULL,
		.h_set = alpha_handle_set,
		.h_commit = NULL,
		.h_export = NULL
};

void settings_usage_init(void)
{
	int rc;

	rc = settings_subsys_init();
	if (rc) {
		LOG_ERR("settings subsys initialization: fail (err %d) ", rc);
		return;
	}

	LOG_INF("settings subsys initialization: OK.");

	rc = settings_register(&alph_handler);
	if (rc) {
		printk("subtree <%s> handler registered: fail (err %d)",
		       alph_handler.name, rc);
	}

	/* load all key-values at once
	 * In case a key-value doesn't exist in the storage
	 * default valuse should be assigned to settings variable
	 * before any settings load call
	 */
	LOG_INF("Load all key-value pairs using registered handlers");
	settings_load();

	if(reboot_cnt == 0)
	{
		LOG_INF("save key_s By Settings API");
		key_s[0] = 0x30;
		key_s[1] = 0x31;
		key_s[2] = 0x32;
		key_s[3] = 0x33;
		key_s[4] = 0x34;
		key_s[5] = 0x35;
		key_s[6] = 0x36;
		key_s[7] = 0x37;		
		rc = settings_save_one("alpha/key", (const void *)key_s,
					sizeof(key_s));
		if (rc) {
			LOG_ERR("key_s save err %d ", rc);
		}		
	}

	LOG_INF("save new reboot counter by Settings API");
	reboot_cnt++;	
	rc = settings_save_one("alpha/boot_cnt", (const void *)&reboot_cnt,
			       sizeof(reboot_cnt));
	if (rc) {
		LOG_ERR("boot_cnt save err %d ", rc);
	}	

}
void flash_thread(void)
{	
	
	LOG_INF("**Flash access example using both NVS and settings API");	

	nvs_usage_init();

	settings_usage_init();

	while (1) {
		//LOG_INF("Flash thread");
		k_sleep(K_SECONDS(1));  
	}
}

K_THREAD_DEFINE(flash_thread_id, 1024, flash_thread, NULL, NULL,
		NULL, 9, 0, 0);
```

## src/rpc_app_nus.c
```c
/*
 * Copyright (c) 2020 Nordic Semiconductor ASA
 *
 * SPDX-License-Identifier: LicenseRef-BSD-5-Clause-Nordic
 */
#include <errno.h>
#include <init.h>

#include <tinycbor/cbor.h>

#include <nrf_rpc_cbor.h>

#include "../../common_ids.h"

#define CBOR_BUF_SIZE 16

static void (*result_callback)(uint8_t *buffer, uint16_t length);


NRF_RPC_GROUP_DEFINE(rpc_nus, "rpc_nus", NULL, NULL, NULL);

int rpc_app_register_bt_recv_cb(void (*callback)(uint8_t *buffer,
							     uint16_t length))
{
	if (callback == NULL) {
		return -NRF_EINVAL;
	}

	result_callback = callback;

	return 0;
}

static void rsp_error_code_handle(CborValue *value, void *handler_data)
{
	CborError cbor_err;

	if (!cbor_value_is_integer(value)) {
		*(int *)handler_data = -NRF_EINVAL;
	}

	cbor_err = cbor_value_get_int(value, (int *)handler_data);
	if (cbor_err != CborNoError) {
		*(int *)handler_data = -NRF_EINVAL;
	}
}

int rpc_app_bt_nus_send(uint8_t *buffer, uint16_t length)
{
	int err;
	int result;
	struct nrf_rpc_cbor_ctx ctx;

	if (!buffer || length < 1) {
		return -NRF_EINVAL;
	}	

	NRF_RPC_CBOR_ALLOC(ctx, CBOR_BUF_SIZE + length);
	
	cbor_encode_byte_string(&ctx.encoder, buffer, length);	

	err = nrf_rpc_cbor_cmd(&rpc_nus, RPC_COMMAND_APP_BT_NUS_SEND, &ctx,
			       rsp_error_code_handle, &result);
	if (err < 0) {
		return err;
	}

	return result;
}

static void rpc_app_bt_receive_cb(CborValue *value, void *handler_data)
{	
	CborError cbor_err;
	int err;
	size_t length;
	uint8_t buf[270];
	
	if (result_callback == NULL) {
		nrf_rpc_cbor_decoding_done(value);
		return;
	}

	err = 0;	
	length = sizeof(buf);
	cbor_err = cbor_value_copy_byte_string(value, buf, &length, NULL);

	if (cbor_err != CborNoError || length < 0 || length > sizeof(buf)) {
		err = -NRF_EBADMSG;		
	}
	else
	{
		result_callback(buf, length);
	}

	nrf_rpc_cbor_decoding_done(value);

	struct nrf_rpc_cbor_ctx ctx;

	NRF_RPC_CBOR_ALLOC(ctx, CBOR_BUF_SIZE);

	cbor_encode_int(&ctx.encoder, err);	

	nrf_rpc_cbor_rsp_no_err(&ctx);
}


NRF_RPC_CBOR_CMD_DECODER(rpc_nus, rpc_app_bt_receive,
			 RPC_COMMAND_NET_BT_NUS_RECEIVE_CB,
			 rpc_app_bt_receive_cb, NULL);
```

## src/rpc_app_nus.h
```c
/*
 * Copyright (c) 2020 Nordic Semiconductor ASA
 *
 * SPDX-License-Identifier: Apache-2.0
 */

#ifndef RPC_APP_NUS_H_
#define RPC_APP_NUS_H_

#include <zephyr/types.h>

/**
 * @file
 * @defgroup entropy_ser Entropy driver serialization
 * @{
 * @brief Entropy serialization API.
 */

#ifdef __cplusplus
extern "C" {
#endif

int rpc_app_bt_nus_send(uint8_t *buffer, uint16_t length);
int rpc_app_register_bt_recv_cb(void (*callback)(uint8_t *buffer,
							     uint16_t length));

#ifdef __cplusplus
}
#endif

/**
 * @}
 */

#endif /* RPC_APP_NUS_H_ */
```

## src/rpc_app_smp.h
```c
/*
 * Copyright (c) 2020 Nordic Semiconductor ASA
 *
 * SPDX-License-Identifier: Apache-2.0
 */

#ifndef RPC_APP_SMP_H_
#define RPC_APP_SMP_H_

#include <zephyr/types.h>

/**
 * @file
 * @defgroup entropy_ser Entropy driver serialization
 * @{
 * @brief Entropy serialization API.
 */

#ifdef __cplusplus
extern "C" {
#endif

int smp_rpc_init(void);
int rpc_app_bt_nus_send(uint8_t *buffer, uint16_t length);
int rpc_app_register_bt_recv_cb(void (*callback)(uint8_t *buffer,
							     uint16_t length));

#ifdef __cplusplus
}
#endif

/**
 * @}
 */

#endif /* RPC_APP_SMP_H_ */
```

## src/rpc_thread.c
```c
/*
 * Copyright (c) 2020 Nordic Semiconductor ASA
 *
 * SPDX-License-Identifier: LicenseRef-BSD-5-Clause-Nordic
 */

#include <zephyr.h>
#include <device.h>
#include <devicetree.h>
#include <drivers/gpio.h>
#include <stdio.h>
#include "rpc_app_api.h"
#include <logging/log.h>
#include <drivers/uart.h>

#define LOG_MODULE_NAME rpc_thread
LOG_MODULE_REGISTER(LOG_MODULE_NAME);

extern struct k_sem sem_rpc_tx;

static void app2net_send_example(void)
{
	static uint8_t cnt;
	int err;
	uint8_t buffer[20];


	snprintf(buffer, 10, "RPC_app_%d", cnt++);		
	buffer[9] = 0;		
	err = app2net_send_nus(buffer, 10);
	if (err) {
		LOG_ERR("app2net nus send err %d", err);			
	}
	else
	{
		LOG_HEXDUMP_INF(buffer, 10, "app2net nus:");
	}	
}

void rpc_thread(void)
{
	LOG_INF("**dual core communication example by RPC encapsulated API");

	k_sem_take(&sem_rpc_tx, K_FOREVER);	

	while (1) {	
		LOG_INF("RPC thread @ appcore");		
		app2net_send_example();
		k_sleep(K_SECONDS(2));
	}
}

K_THREAD_DEFINE(rpc_thread_id, 1024, rpc_thread, NULL, NULL,
		NULL, 6, 0, 0);
```

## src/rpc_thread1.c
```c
/*
 * Copyright (c) 2020 Nordic Semiconductor ASA
 *
 * SPDX-License-Identifier: LicenseRef-BSD-5-Clause-Nordic
 */

#include <zephyr.h>
#include <device.h>
#include <devicetree.h>
#include <drivers/gpio.h>
#include <stdio.h>
#include "rpc_app_nus.h"
#include "rpc_app_api.h"
#include <logging/log.h>
#include <drivers/uart.h>

#define LOG_MODULE_NAME rpc_thread1
LOG_MODULE_REGISTER(LOG_MODULE_NAME);

extern struct k_sem sem_rpc_tx;

#ifdef CONFIG_RPC_NUS_DEDICATE

#define BUFFER_LENGTH 64
static uint8_t buffer[BUFFER_LENGTH];	

static void bt_recv_cb(uint8_t *buffer, uint16_t length)
{
	LOG_INF("received ble data from netcore");
	LOG_HEXDUMP_INF(buffer, length, "data:");
}

static void app2net_tx1(void)
{
	static uint8_t cnt;
	int err;

	snprintf(buffer, 12, "HelloApp%d", cnt++);		
	buffer[11] = 0;		
	err = rpc_app_bt_nus_send(buffer, 12);
	if (err) {
		LOG_ERR("rpc_app_bt_nus_send failed: %d\n", err);			
	}
	else
	{
		LOG_HEXDUMP_INF(buffer, 12, "sent by app core:");
	}

}
#endif

static void app2net_tx2(void)
{
	static uint8_t cnt;
	int err;
	uint8_t buffer[20];


	snprintf(buffer, 10, "RPC_app_%d", cnt++);		
	buffer[9] = 0;		
	err = app2net_send_nus(buffer, 10);
	if (err) {
		LOG_ERR("app2net nus send err %d", err);			
	}
	else
	{
		LOG_HEXDUMP_INF(buffer, 10, "app2net nus:");
	}	
}

void rpc_thread1(void)
{
	LOG_INF("**dual core communication example by RPC encapsulated API");

#ifdef CONFIG_RPC_NUS_DEDICATE	
    rpc_app_register_bt_recv_cb(bt_recv_cb);
#endif	
	k_sem_take(&sem_rpc_tx, K_FOREVER);	

	while (1) {	
		LOG_INF("RPC thread @ appcore");
#ifdef CONFIG_RPC_NUS_DEDICATE				
		app2net_tx1();
		k_sleep(K_SECONDS(2));
#endif			
		app2net_tx2();
		k_sleep(K_SECONDS(2));
	}
}

K_THREAD_DEFINE(rpc_thread_id1, 1024, rpc_thread1, NULL, NULL,
		NULL, 6, 0, 0);
```

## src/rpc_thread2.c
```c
/*
 * Copyright (c) 2020 Nordic Semiconductor ASA
 *
 * SPDX-License-Identifier: LicenseRef-BSD-5-Clause-Nordic
 */

#include <zephyr.h>
#include <device.h>
#include <devicetree.h>
#include <drivers/gpio.h>
#include <stdio.h>
#include "rpc_app_nus.h"
#include "nrf_rpc_tr.h"
#include <logging/log.h>
#include <drivers/uart.h>

#define LOG_MODULE_NAME rpc_thread2
LOG_MODULE_REGISTER(LOG_MODULE_NAME);

extern struct k_sem sem_rpc_tx;

#define BUFFER_LENGTH 64

static uint8_t buffer[BUFFER_LENGTH];

static bool m_is_connected;
bool get_ble_connection_status(void)
{
	return m_is_connected;
}

void set_ble_connection_status(bool is_connected)
{
	m_is_connected = is_connected;
}


#ifdef CONFIG_EXAMPLE_HS_UART
extern int my_uart_send(const uint8_t *buf, size_t len);
#endif
/*
* format: 0x55 CMD LEN Payload 0xAA (Checksum)
* 0x55 0x01 0x01 0x00 0xAA  //connected
* 0x55 0x01 0x01 0x01 0xAA  //disconnected
*/
/* Callback from transport layer that handles incoming. */
static void rpc_receive_handler(const uint8_t *packet, size_t len)
{
	
	LOG_INF("received data from net core by RPC");
	LOG_HEXDUMP_INF(packet, len, "packet:");

#ifdef CONFIG_EXAMPLE_HS_UART
	my_uart_send(packet, len);
#endif
	if(packet[0] == 0x55)
	{
		if (packet[1] == 0x01)
		{
			if (packet[2] == 0x01)
			{
				set_ble_connection_status(packet[3] == 0);
			}
		}		
	}
	if (!NRF_RPC_TR_AUTO_FREE_RX_BUF) {
		nrf_rpc_tr_free_rx_buf(packet);
	}
}


static void rpc_init(void)
{
	int err = nrf_rpc_tr_init(rpc_receive_handler);
	if (err < 0) {
		LOG_ERR("rpc tr init error %d \n", err);
		return;
	}	

}

static void rpc_tx_app(void)
{
	static uint8_t cnt;
	int err;

	snprintf(buffer, 12, "HelloApp%d", cnt++);		
	buffer[11] = 0;		
	err = nrf_rpc_tr_send(buffer, 12);
	if (err) {
		LOG_ERR("nrf_rpc_tr_send failed: %d\n", err);			
	}
	else
	{
		LOG_HEXDUMP_INF(buffer, 12, "Sent by app core:");
	}

}

void rpc_thread2(void)
{
	LOG_INF("**dual core interactions by RPC raw API");
    rpc_init();

	while (1) {        
		k_sem_take(&sem_rpc_tx, K_FOREVER);	
		LOG_INF("RPC thread\n");	
		rpc_tx_app();
		k_sleep(K_SECONDS(2));
	}
}

K_THREAD_DEFINE(rpc_thread_id2, 1024, rpc_thread2, NULL, NULL,
		NULL, 6, 0, 0);
```

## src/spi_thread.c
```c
/*
 * Copyright (c) 2020 Nordic Semiconductor ASA
 *
 * SPDX-License-Identifier: LicenseRef-BSD-5-Clause-Nordic
 */

#include <zephyr.h>
#include <device.h>
#include <devicetree.h>
#include <drivers/gpio.h>
#include <logging/log.h>
#include <drivers/spi.h>

#define LOG_MODULE_NAME spi_thread
LOG_MODULE_REGISTER(LOG_MODULE_NAME);

#define SPI_DEVICE_NAME         "SPI_3"
#define PIN_SPIM_CS	12  //P1.12
#define DELAY_SPI_CS_ACTIVE_US 2
#define TEST_STRING "Nordic"

const struct device *spi_dev;
extern struct k_sem sem_spi_txrx;

static int spi_data_exchange(void)
{
    int err;
    struct spi_cs_control cs_ctrl;
    struct spi_config spi_cfg = {0};

	spi_cfg.frequency = 8000000U;
	spi_cfg.operation = SPI_WORD_SET(8);	

	cs_ctrl.gpio_dev =
		device_get_binding("GPIO_1");
	if (!cs_ctrl.gpio_dev) {
        LOG_ERR("cannot find GPIO_1 device");
		return -ENODEV;
	}

	cs_ctrl.gpio_pin = PIN_SPIM_CS;
	cs_ctrl.gpio_dt_flags = GPIO_ACTIVE_LOW;
	cs_ctrl.delay = DELAY_SPI_CS_ACTIVE_US;

	spi_cfg.cs = &cs_ctrl;

	uint8_t buf[] = TEST_STRING;
    uint8_t data[] = TEST_STRING;

	struct spi_buf spi_buf[2] = {
		{
			.buf = buf,
			.len = sizeof(buf),
		},
		{
			.buf = data,
			.len = sizeof(data)
		}
	};
    
	const struct spi_buf_set tx_set = {
		.buffers = spi_buf,
		.count = 1
	};

	const struct spi_buf_set rx_set = {
		.buffers = spi_buf,
		.count = 1
	};

	// const struct spi_buf_set tx_set = {
	// 	.buffers = spi_buf,
	// 	.count = 2
	// };

	// const struct spi_buf_set rx_set = {
	// 	.buffers = spi_buf,
	// 	.count = 2
	// };    

	err = spi_transceive(spi_dev, &spi_cfg, &tx_set, &rx_set);
    
    if (err)
    {
        LOG_ERR("SPI transcation failed err %d", err);
    }
    else
    {
        LOG_HEXDUMP_INF(rx_set.buffers->buf, rx_set.buffers->len, "Received SPI data: ");
    }

    return err;

}

void spi_thread(void)
{	
	
	LOG_INF("**SPI master example working with nRF5_SDK\\examples\\peripheral\\spis directly");	

	spi_dev = device_get_binding(SPI_DEVICE_NAME);
	if (!spi_dev) {
		LOG_ERR("SPIM driver not found.\n");
		return;
	}
    k_sem_take(&sem_spi_txrx, K_FOREVER);
	while (1) {                
        LOG_INF("spi master thread");
        spi_data_exchange();
        k_sleep(K_MSEC(200)); 
	}
}

K_THREAD_DEFINE(spi_thread_id, 1024, spi_thread, NULL, NULL,
		NULL, 7, 0, 0);
```

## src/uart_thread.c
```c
/*
 * Copyright (c) 2020 Nordic Semiconductor ASA
 *
 * SPDX-License-Identifier: LicenseRef-BSD-5-Clause-Nordic
 */

#include <zephyr.h>
#include <device.h>
#include <devicetree.h>
#include <drivers/gpio.h>
#include <stdio.h>
#include <logging/log.h>
#include <drivers/uart.h>
#include "nrf_rpc_tr.h"
#include "rpc_app_api.h"

#define LOG_MODULE_NAME uart_thread
LOG_MODULE_REGISTER(LOG_MODULE_NAME);

#define UART_DEVICE_NAME         DT_LABEL(DT_NODELABEL(uart1))

#define UART_BUF_SIZE 255
#define UART_WAIT_FOR_BUF_DELAY K_MSEC(100)
#define UART_WAIT_FOR_RX 50

static const struct device *uart;

struct uart_data_t {
	void *fifo_reserved;
	uint8_t data[UART_BUF_SIZE];
	uint16_t len;
};

static uint8_t uart_rx_buf[2][UART_BUF_SIZE];
static uint8_t *next_buf = uart_rx_buf[1];

static K_FIFO_DEFINE(fifo_uart_tx_data);
static K_FIFO_DEFINE(fifo_uart_rx_data);


static void uart_cb(const struct device *dev, struct uart_event *evt, void *user_data)
{
	ARG_UNUSED(dev);
	int err;

	switch (evt->type) {
	case UART_TX_DONE:
	{
		struct uart_data_t *buf;
		struct uart_data_t *buf2;
		
		buf = CONTAINER_OF(evt->data.tx.buf, struct uart_data_t,  data);		
		LOG_INF("UART_TX_DONE %d", evt->data.tx.len);
		k_free(buf);

		buf2 = k_fifo_get(&fifo_uart_tx_data, K_NO_WAIT);
		if (!buf2) {
			return;
		}

		if (uart_tx(uart, buf2->data, buf2->len, SYS_FOREVER_MS)) {
			LOG_WRN("uart_tx fail @ cb");
		}
	}
		break;

	case UART_RX_RDY:
	{
		struct uart_data_t *buf = k_malloc(sizeof(struct uart_data_t));
		memcpy(buf->data, &evt->data.rx.buf[evt->data.rx.offset], evt->data.rx.len);	
		buf->len = evt->data.rx.len;		
		k_fifo_put(&fifo_uart_rx_data, buf);
		LOG_INF("UART_RX_RDY %d", buf->len);
	}
		break;

	case UART_RX_DISABLED:
		LOG_INF("UART_RX_DISABLED");
		err = uart_rx_enable(uart, uart_rx_buf[0], sizeof(uart_rx_buf[0]), UART_WAIT_FOR_RX);
		if (err) {
			LOG_ERR("UART RX enable failed: %d", err);			
		}
		break;

	case UART_RX_BUF_REQUEST:
		err = uart_rx_buf_rsp(uart, next_buf,
			sizeof(uart_rx_buf[0]));
		if (err) {
			LOG_WRN("UART RX buf rsp: %d", err);
		}		
		break;

	case UART_RX_BUF_RELEASED:
		LOG_INF("UART_RX_BUF_RELEASED");
		next_buf = evt->data.rx_buf.buf;
		break;

	case UART_TX_ABORTED:
		LOG_INF("UART_TX_ABORTED");
		break;

	default:
		break;
	}
}

static int uart_init(void)
{
	int err;
	
	uart = device_get_binding(UART_DEVICE_NAME);
	if (!uart) {
		return -ENXIO;
	}

	err = uart_callback_set(uart, uart_cb, NULL);
	if (err) {
		return err;
	}

	return uart_rx_enable(uart, uart_rx_buf[0], sizeof(uart_rx_buf[0]), UART_WAIT_FOR_RX);

}

int my_uart_send(const uint8_t *buf, size_t len)
{
	int err;
	struct uart_data_t *tx = k_malloc(sizeof(*tx));

	if (!tx) {
		LOG_WRN("Not able to allocate UART send data buffer");
		return -ENOMEM; 
	}

	memcpy(tx->data, buf, len);	
	tx->len = len;
	err = uart_tx(uart, tx->data, tx->len, SYS_FOREVER_MS);
	if (err) {
		LOG_WRN("buffer uart tx data for later retry");
		k_fifo_put(&fifo_uart_tx_data, tx);
	}
	return err;		
}

void uart_thread(void)
{    
	static uint32_t uart_len;	

	LOG_INF("**high speed UART example");
	uart_init();

	while (1) {

		/* Send the UART data back to the peer. Wait indefinitely*/
		struct uart_data_t *buf = k_fifo_get(&fifo_uart_rx_data,
						     K_FOREVER);
#ifdef CONFIG_RPC_REMOTE_API
		if (is_ble_connected())
		{
			int err = app2net_send_nus(buf->data,buf->len);
			if (err) {
				LOG_WRN("app2net_send_nus err %d", err);			
			}	
		}
#endif

		my_uart_send(buf->data,buf->len);

		uart_len += buf->len;
		LOG_INF("uart rx total len %d and %d", uart_len, buf->len);
		k_free(buf);					
	}
}

K_THREAD_DEFINE(uart_thread_id, 1024, uart_thread, NULL, NULL,
		NULL, 5, 0, 0);
```
